# sifive_qemu_sifive_e_32 register map
File version: 0.1
From sifive,qemu_sifive_e_32,model device generator
Registers are 32-bit, read-write, no defined reset value unless marked. A register's access mark holds for its fields unless they carry their own. Offsets are from the block's base; lines under a group give offsets from that group; [hi:lo] are bit positions; {n}, {i} and the like mark numbered series; 'fields as' and 'values as' point back to an identical list; <NAME> marks a mode.

## Memory map
0x02000000 riscv_clint0_0 size 0x10000 — From riscv,clint0,control peripheral generator
0x0C000000 riscv_plic0_0 size 0x4000000 — From riscv,plic0,control peripheral generator
0x10013000 sifive_uart0_0 size 0x1000 — From sifive,uart0,control peripheral generator
0x10014000 sifive_spi0_0 size 0x1000 — From sifive,spi0,control peripheral generator
0x10023000 sifive_uart0_1 size 0x1000 — From sifive,uart0,control peripheral generator

## riscv_clint0_0 — From riscv,clint0,control peripheral generator
Base 0x02000000
0x00 msip_0 — MSIP Register for hart 0
0x4000 mtimecmp_0 64-bit — MTIMECMP Register for hart 0
0xBFF8 mtime 64-bit

## riscv_plic0_0 — From riscv,plic0,control peripheral generator
Base 0x0C000000
{0x0+4i} priority_{i} (i=1..54) — PRIORITY Register for interrupt id {i}
0x1000 pending_0 — PENDING Register for interrupt ids 31 to 0
0x1004 pending_1 — PENDING Register for interrupt ids 54 to 32
0x2000 enable_0_0 — ENABLE Register for interrupt ids 31 to 0 for hart 0
0x2004 enable_1_0 — ENABLE Register for interrupt ids 54 to 32 for hart 0
0x200000 threshold_0 — PRIORITY THRESHOLD Register for hart 0
0x200004 claimplete_0 — CLAIM and COMPLETE Register for hart 0

## sifive_uart0_0 — From sifive,uart0,control peripheral generator
Base 0x10013000
Same registers: sifive_uart0_1 0x10023000
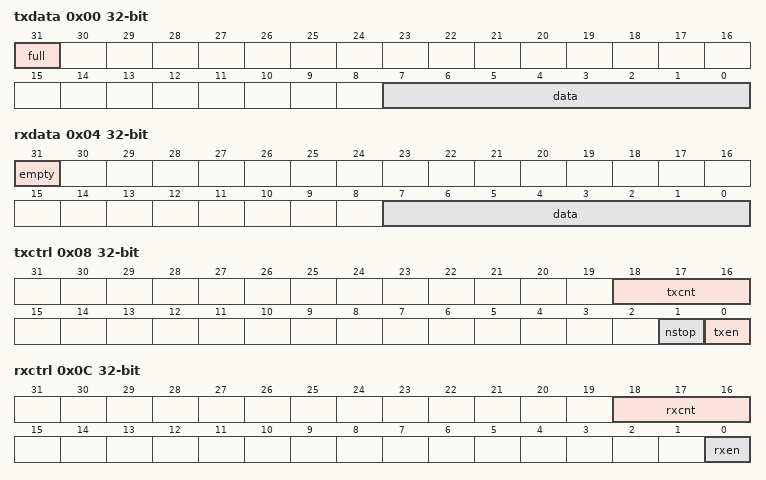
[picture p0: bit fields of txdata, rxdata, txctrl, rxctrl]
0x00 txdata — Transmit data register
  [31] full ro — Transmit FIFO full
  [7:0] data — Transmit data
0x04 rxdata — Receive data register
  [31] empty ro — Receive FIFO empty
  [7:0] data ro — Received data
0x08 txctrl — Transmit control register
  [18:16] txcnt — Transmit watermark level
  [1] nstop — Number of stop bits
  [0] txen — Transmit enable
0x0C rxctrl — Receive control register
  [18:16] rxcnt — Receive watermark level
  [0] rxen — Receive enable
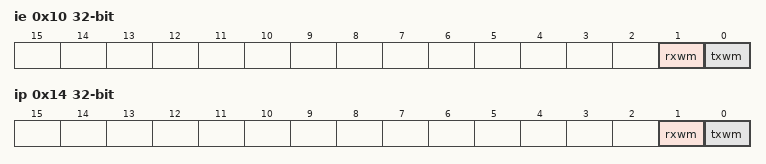
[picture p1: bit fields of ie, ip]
0x10 ie — UART interrupt enable
  [1] rxwm — Receive watermark interrupt enable
  [0] txwm — Transmit watermark interrupt enable
0x14 ip — UART interrupt pending
  [1] rxwm ro — Receive watermark interrupt pending
  [0] txwm ro — Transmit watermark interrupt pending
0x18 div — Baud rate divisor
  [15:0] div — Baud rate divisor.

## sifive_spi0_0 — From sifive,spi0,control peripheral generator
Base 0x10014000
0x00 sckdiv — Serial clock divisor
  [11:0] div — Divisor for serial clock.
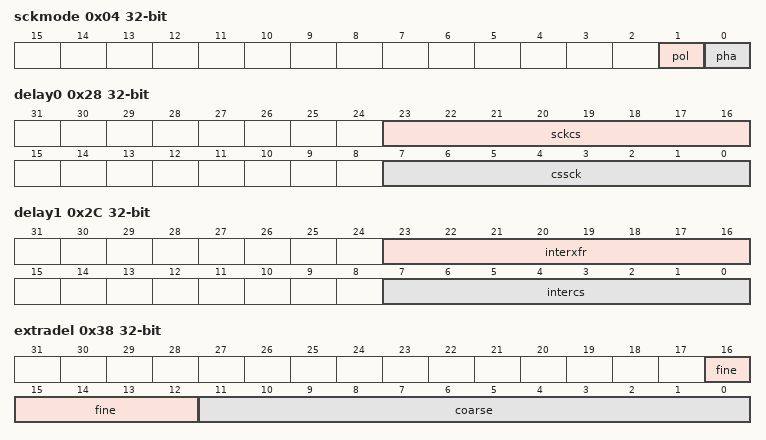
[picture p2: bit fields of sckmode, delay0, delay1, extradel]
0x04 sckmode — Serial clock mode
  [1] pol — Serial clock polarity
  [0] pha — Serial clock phase
0x10 csid — Chip select ID
  [31:0] csid — Chip select ID.
0x14 csdef — Chip select default
  [31:0] csdef — Chip select default value. Reset to all-1s.
0x18 csmode — Chip select mode
  [1:0] mode
0x28 delay0 — Delay control 0
  [23:16] sckcs — SCK to CS Delay
  [7:0] cssck — CS to SCK Delay
0x2C delay1 — Delay control 1
  [23:16] interxfr — Maximum interframe delay
  [7:0] intercs — Minimum CS inactive time
0x38 extradel — SPI extra sampling delay to increase the SPI frequency
  [16:12] fine — Fine grain sample delay (multiples of process-specific buffer delay)
  [11:0] coarse — Coarse grain sample delay (multiples of system clocks)
0x3C sampledel — Number of delay stages from slave to the SPI controller
  [4:0] sd — Number of delay stages from slave to SPI controller
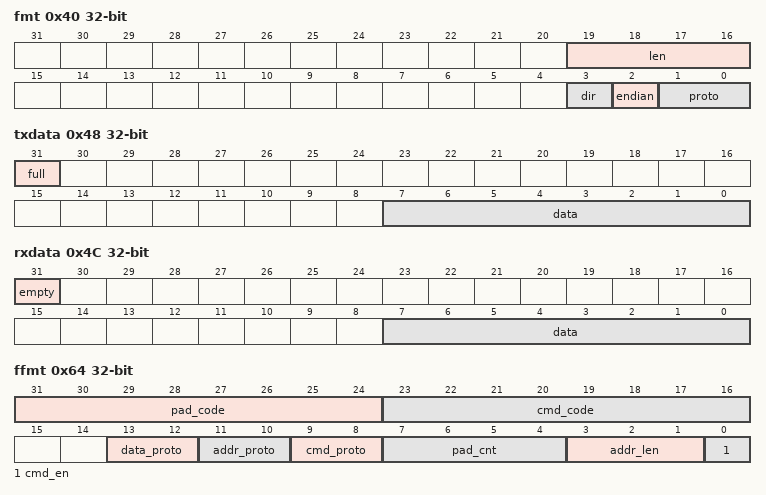
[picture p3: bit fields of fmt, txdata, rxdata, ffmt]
0x40 fmt — Frame format
  [19:16] len — Number of bits per frame
  [3] dir — SPI I/O direction. This is reset to 1 for flash-enabled SPI controllers, 0 otherwise.
  [2] endian — SPI endianness
  [1:0] proto — SPI protocol
0x48 txdata — Tx FIFO Data
  [31] full ro — FIFO full flag
  [7:0] data — Transmit data
0x4C rxdata — Rx FIFO data
  [31] empty — FIFO empty flag
  [7:0] data ro — Received data
0x50 txmark — Tx FIFO watermark
  [2:0] txmark — Transmit watermark. The reset value is 1 for flash-enabled controllers, 0 otherwise.
0x54 rxmark — Rx FIFO watermark
  [2:0] rxmark — Receive watermark
0x60 fctrl — SPI flash interface control
  [0] en — SPI Flash Mode Select
0x64 ffmt — SPI flash instruction format
  [31:24] pad_code — First 8 bits to transmit during dummy cycles
  [23:16] cmd_code — Value of command byte
  [13:12] data_proto — Protocol for receiving data bytes
  [11:10] addr_proto — Protocol for transmitting address and padding
  [9:8] cmd_proto — Protocol for transmitting command
  [7:4] pad_cnt — Number of dummy cycles
  [3:1] addr_len — Number of address bytes (0 to 4)
  [0] cmd_en — Enable sending of command
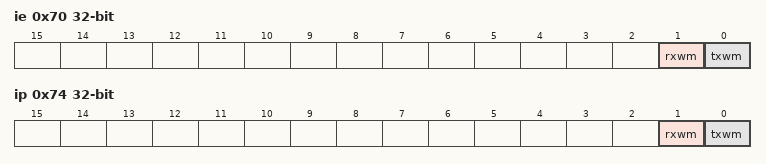
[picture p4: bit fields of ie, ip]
0x70 ie — SPI interrupt enable
  [1] rxwm — Receive watermark enable
  [0] txwm — Transmit watermark enable
0x74 ip — SPI interrupt pending
  [1] rxwm ro — Receive watermark pending
  [0] txwm ro — Transmit watermark pending
